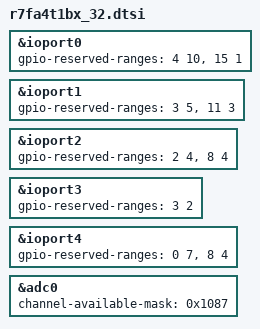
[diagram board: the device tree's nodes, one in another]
/*
 * Copyright (c) 2025 Renesas Electronics Corporation
 *
 * SPDX-License-Identifier: Apache-2.0
 */

#include <arm/renesas/ra/ra4/r7fa4t1bx.dtsi>

/delete-node/ &ioport5;
/delete-node/ &ioport8;
/delete-node/ &pwm3;
/delete-node/ &pwm4;
/delete-node/ &dac1;

&ioport0 {
	gpio-reserved-ranges = <4 10>, <15 1>;
};

&ioport1 {
	gpio-reserved-ranges = <3 5>, <11 3>;
};

&ioport2 {
	gpio-reserved-ranges = <2 4>, <8 4>;
};

&ioport3 {
	gpio-reserved-ranges = <3 2>;
};

&ioport4 {
	gpio-reserved-ranges = <0 7>, <8 4>;
};

&adc0 {
	channel-available-mask = <0x1087>;
};
